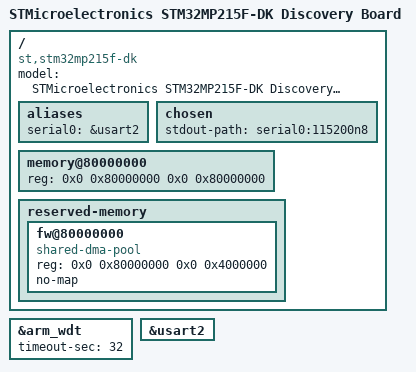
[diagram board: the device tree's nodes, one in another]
// SPDX-License-Identifier: (GPL-2.0-only OR BSD-3-Clause)
/*
 * Copyright (C) STMicroelectronics 2025 - All Rights Reserved
 * Author: Amelie Delaunay <amelie.delaunay@foss.st.com> for STMicroelectronics.
 */

/dts-v1/;

#include "stm32mp215.dtsi"
#include "stm32mp21xf.dtsi"

/ {
	model = "STMicroelectronics STM32MP215F-DK Discovery Board";
	compatible = "st,stm32mp215f-dk", "st,stm32mp215";

	aliases {
		serial0 = &usart2;
	};

	chosen {
		stdout-path = "serial0:115200n8";
	};

	memory@80000000 {
		device_type = "memory";
		reg = <0x0 0x80000000 0x0 0x80000000>;
	};

	reserved-memory {
		#address-cells = <2>;
		#size-cells = <2>;
		ranges;

		fw@80000000 {
			compatible = "shared-dma-pool";
			reg = <0x0 0x80000000 0x0 0x4000000>;
			no-map;
		};
	};
};

&arm_wdt {
	timeout-sec = <32>;
	status = "okay";
};

&usart2 {
	status = "okay";
};
